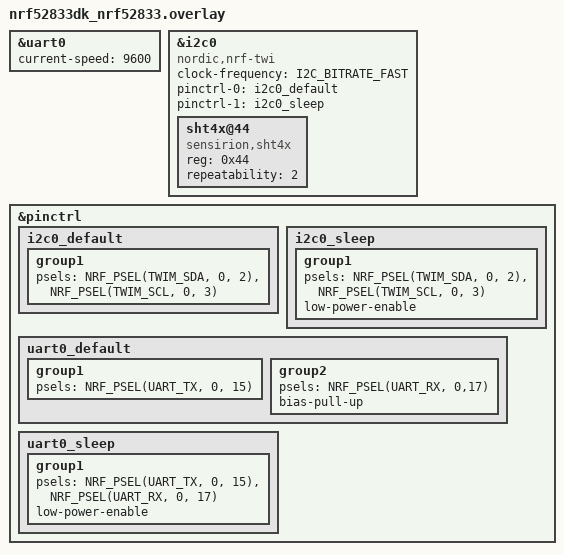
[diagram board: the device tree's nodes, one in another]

&uart0 {
	status = "okay";
	current-speed = < 9600 >; /* Default 115200 */
};


&i2c0 {
	status = "okay";
	clock-frequency = <I2C_BITRATE_FAST>;
	sht4x@44 {
		status = "okay";
		compatible = "sensirion,sht4x";
		reg = <0x44>;
		repeatability = <2>;
	};
	// sgp40@59 {
	// 	status = "okay";
	// 	compatible = "sensirion,sgp40";
	// 	reg = <0x59>;
	// 	enable-selftest;
	// };
};

&i2c0 {
	compatible = "nordic,nrf-twi";
	status = "okay";
	pinctrl-0 = <&i2c0_default>;
	pinctrl-1 = <&i2c0_sleep>;
	pinctrl-names = "default", "sleep";
};
&pinctrl {
	i2c0_default: i2c0_default {
		group1 {
			psels = <NRF_PSEL(TWIM_SDA, 0, 2)>,
					<NRF_PSEL(TWIM_SCL, 0, 3)>;
		};
	};

	i2c0_sleep: i2c0_sleep {
		group1 {
			psels = <NRF_PSEL(TWIM_SDA, 0, 2)>,
					<NRF_PSEL(TWIM_SCL, 0, 3)>;
			low-power-enable;
		};
	};
	uart0_default: uart0_default {
		group1 {
			psels = <NRF_PSEL(UART_TX, 0, 15)>;
		};
		group2 {
			psels = <NRF_PSEL(UART_RX, 0,17)>;
			bias-pull-up;
		};
	};

	uart0_sleep: uart0_sleep {
		group1 {
			psels = <NRF_PSEL(UART_TX, 0, 15)>,
					<NRF_PSEL(UART_RX, 0, 17)>;
			low-power-enable;
		};
	};

};




